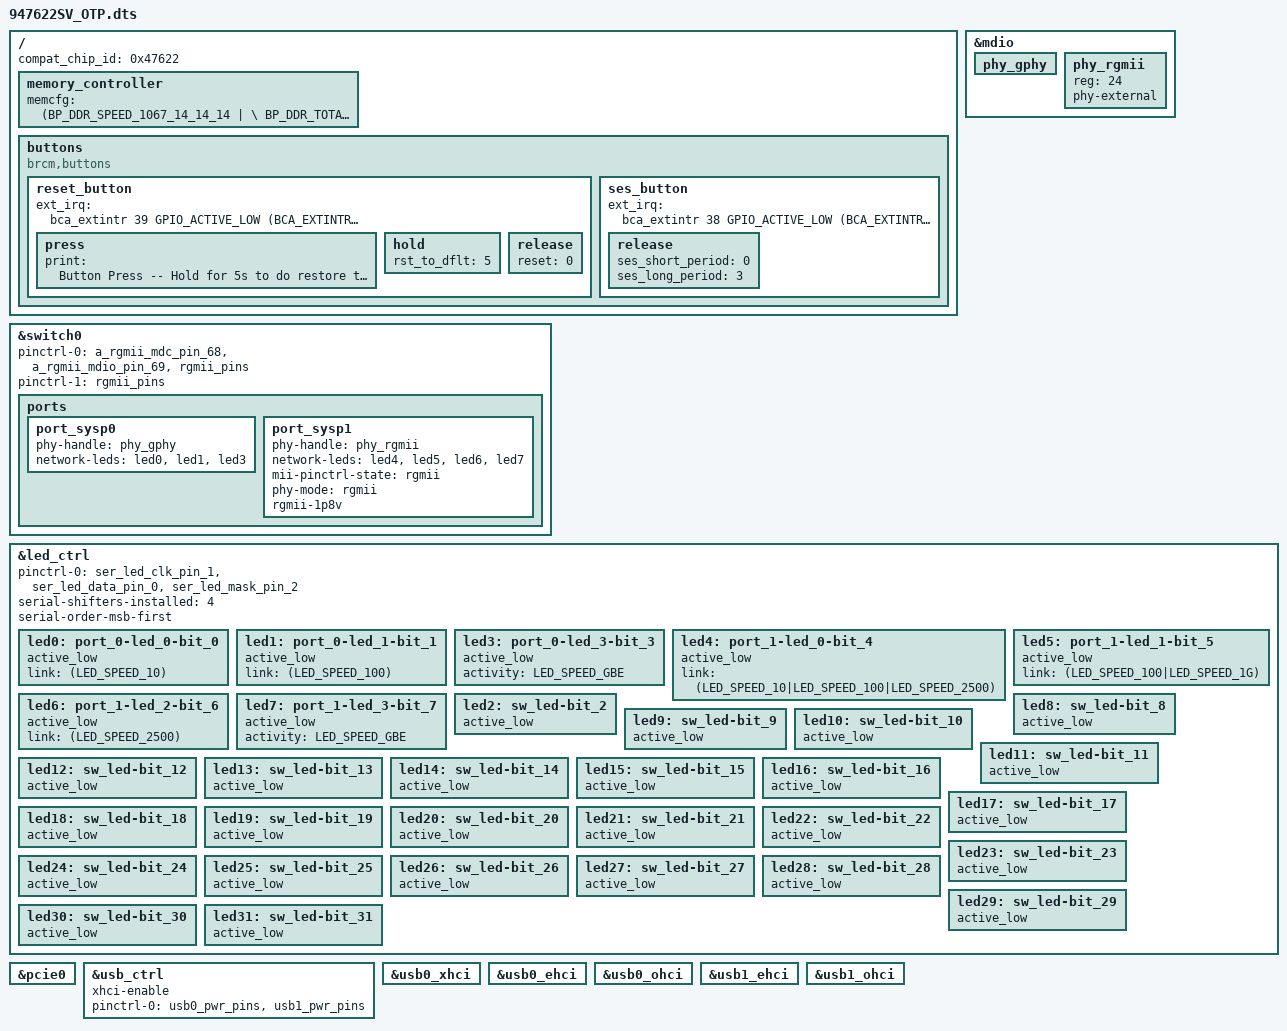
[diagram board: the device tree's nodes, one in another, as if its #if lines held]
#include "47622.dtsi"

/ {
	compat_chip_id = <0x47622>;
    memory_controller {
        memcfg = <(BP_DDR_SPEED_1067_14_14_14 | \
                   BP_DDR_TOTAL_SIZE_512MB    | \
                   BP_DDR_DEVICE_WIDTH_16     | \
                   BP_DDR_TOTAL_WIDTH_16BIT   | \
                   BP_DDR_SSC_CONFIG_1)>;
    };

	buttons {
		compatible = "brcm,buttons";
		reset_button {
			ext_irq = <&bca_extintr 39 GPIO_ACTIVE_LOW (BCA_EXTINTR_TYPE_LOW_LEVEL | BCA_EXTINTR_TYPE_SENSE_EDGE)>;
			press {
				print = "Button Press -- Hold for 5s to do restore to default";
			};
			hold {
				rst_to_dflt = <5>;
			};
			release {
				reset = <0>;
			};	
		};
		ses_button {
			ext_irq = <&bca_extintr 38 GPIO_ACTIVE_LOW (BCA_EXTINTR_TYPE_LOW_LEVEL | BCA_EXTINTR_TYPE_SENSE_EDGE)>;
			release {
				ses_short_period = <0>;
				ses_long_period = <3>;
			};
		};
	};
};

&mdio {
    /* Port PHY mapping:
            port_sysp0 <-->  phy_gphy
            port_sysp1 <-->  phy_rgmii
     */
	phy_gphy {
		status = "okay";
	};

	phy_rgmii {
		reg = <24>;
		status = "okay";
		phy-external;
	};

};

&switch0 {
	pinctrl-names = "default", "rgmii"; 
	pinctrl-0 = <&a_rgmii_mdc_pin_68 &a_rgmii_mdio_pin_69 &rgmii_pins>; 
	pinctrl-1 = <&rgmii_pins>; 

	ports {
		/* fixed port configuration */
		port_sysp0 {
			phy-handle = <&phy_gphy>;
			network-leds = <&led0 &led1 &led3>;
			status = "okay";
		};
		port_sysp1 {
			phy-handle = <&phy_rgmii>;
			network-leds = <&led4 &led5 &led6 &led7>;	
			mii-pinctrl-state = "rgmii";
			phy-mode = "rgmii";
			rgmii-1p8v;
			status = "okay";
		};
	};
};

&led_ctrl {
	pinctrl-names = "default";
	pinctrl-0 = <&ser_led_clk_pin_1 &ser_led_data_pin_0 &ser_led_mask_pin_2>;
	serial-shifters-installed = <4>;
	serial-order-msb-first;

	led0: port_0-led_0-bit_0 {
		active_low;
		link = <(LED_SPEED_10)>;
		status = "okay";
	};
	led1: port_0-led_1-bit_1 {
		active_low;
		link = <(LED_SPEED_100)>;
		status = "okay";
	};
	led3: port_0-led_3-bit_3 {
		active_low;
		activity = <LED_SPEED_GBE>;
		status = "okay";
	};
	led4: port_1-led_0-bit_4 {
		active_low;
		link = <(LED_SPEED_10|LED_SPEED_100|LED_SPEED_2500)>;
		status = "okay";
	};
	led5: port_1-led_1-bit_5 {
		active_low;
		link = <(LED_SPEED_100|LED_SPEED_1G)>;
		status = "okay";
	};
	led6: port_1-led_2-bit_6 {
		active_low;
		link = <(LED_SPEED_2500)>;
		status = "okay";
	};
	led7: port_1-led_3-bit_7 {
		active_low;
		activity = <LED_SPEED_GBE>;
		status = "okay";
	};
	led2: sw_led-bit_2 {
		active_low;
		status = "okay";
	};
	led8: sw_led-bit_8 {
		active_low;
		status = "okay";
	};
	led9: sw_led-bit_9 {
		active_low;
		status = "okay";
	};
	led10: sw_led-bit_10 {
		active_low;
		status = "okay";
	};
	led11: sw_led-bit_11 {
		active_low;
		status = "okay";
	};
	led12: sw_led-bit_12 {
		active_low;
		status = "okay";
	};
	led13: sw_led-bit_13 {
		active_low;
		status = "okay";
	};
	led14: sw_led-bit_14 {
		active_low;
		status = "okay";
	};
	led15: sw_led-bit_15 {
		active_low;
		status = "okay";
	};
	led16: sw_led-bit_16 {
		active_low;
		status = "okay";
	};
	led17: sw_led-bit_17 {
		active_low;
		status = "okay";
	};
	led18: sw_led-bit_18 {
		active_low;
		status = "okay";
	};
	led19: sw_led-bit_19 {
		active_low;
		status = "okay";
	};
	led20: sw_led-bit_20 {
		active_low;
		status = "okay";
	};
	led21: sw_led-bit_21 {
		active_low;
		status = "okay";
		};
	led22: sw_led-bit_22 {
		active_low;
		status = "okay";
		};
	led23: sw_led-bit_23 {
		active_low;
		status = "okay";
		};
	led24: sw_led-bit_24 {
		active_low;
		status = "okay";
		};
	led25: sw_led-bit_25 {
		active_low;
		status = "okay";
		};
	led26: sw_led-bit_26 {
		active_low;
		status = "okay";
	};
	led27: sw_led-bit_27 {
		active_low;
		status = "okay";
	};
	led28: sw_led-bit_28 {
		active_low;
		status = "okay";
	};
	led29: sw_led-bit_29 {
		active_low;
		status = "okay";
	};
	led30: sw_led-bit_30 {
		active_low;
		status = "okay";
	};
	led31: sw_led-bit_31 {
		active_low;
		status = "okay";
	};
};

#if defined(CONFIG_BCM_PCIE_HCD) || defined (CONFIG_BCM_PCIE_HCD_MODULE)
&pcie0 {
	status = "okay";
};
#endif

&usb_ctrl {
	status = "okay";
	xhci-enable;
	pinctrl-names = "default";
	pinctrl-0 = <&usb0_pwr_pins &usb1_pwr_pins>;
};

&usb0_xhci {
	status = "okay";
};

&usb0_ehci {
	status = "okay";
};

&usb0_ohci {
	status = "okay";
};

&usb1_ehci {
	status = "okay";
};

&usb1_ohci {
	status = "okay";
};

